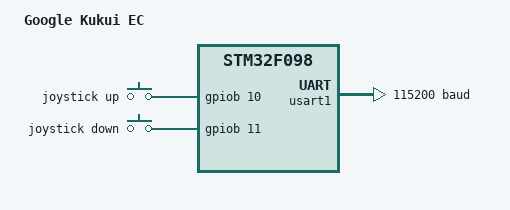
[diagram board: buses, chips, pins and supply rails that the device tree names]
/*
 * Copyright (c) 2019 The Chromium OS Authors
 *
 * SPDX-License-Identifier: Apache-2.0
 */

/dts-v1/;
#include <st/f0/stm32f091Xc.dtsi>

/ {
	model = "Google Kukui EC";
	compatible = "st,stm32f098rc", "st,stm32f098";

	chosen {
		zephyr,console = &usart1;
		zephyr,shell-uart = &usart1;
		zephyr,sram = &sram0;
		zephyr,flash = &flash0;
	};

	gpio_keys {
		compatible = "gpio-keys";
		joy_up: joystick_up {
			label = "joystick up";
			gpios = <&gpiob 10 GPIO_INT_ACTIVE_HIGH>;
		};
		joy_down: joystick_down {
			label = "joystick down";
			gpios = <&gpiob 11 GPIO_INT_ACTIVE_HIGH>;
		};
	};
};

&usart1 {
	current-speed = <115200>;
	pinctrl-0 = <&usart1_pins_a>;
	pinctrl-names = "default";
	status = "okay";
};

&flash0 {
	/*
	 * For more information, see:
	 * http://docs.zephyrproject.org/latest/guides/dts/index.html#flash-partitions
	 */
	partitions {
		compatible = "fixed-partitions";
		#address-cells = <1>;
		#size-cells = <1>;

		/* Set 6Kb of storage at the end of the 256Kb of flash */
		storage_partition: partition@3e800 {
			label = "storage";
			reg = <0x0003e800 0x00001800>;
		};
	};
};

